# AT32UC3L0256 device description
Architecture: AVR32_UC3; Family: AVR UC3
Registers are 32-bit, read-write, reset 0x0 unless marked. A register's access mark holds for its fields unless they carry their own. Offsets are from the block's base; [hi:lo] are bit positions; lines under a group give offsets from that group; {n}, {i} and the like mark numbered series; 'fields as' and 'values as' point back to an identical list.

## GLOC — Glue Logic Controller
Instances: GLOC 0xffff6c00
{0x0+8i} LUT[{i}] (i=0..6) group
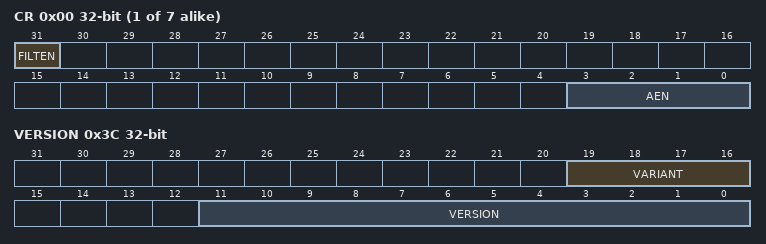
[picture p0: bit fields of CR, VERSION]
  0x00 CR — Control Register
    [31] FILTEN — Filter enable
    [3:0] AEN — Input mask
  0x04 TRUTH
    [15:0] TRUTH
0x38 PARAMETER ro reset not defined
  [7:0] LUTS
0x3C VERSION ro reset not defined
  [19:16] VARIANT, [11:0] VERSION

## HMATRIXB — HSB Matrix
Instances: HMATRIXB 0xfffe0400
{0x0+4i} mcfg[{i}] (i=0..15) access not given reset 0x2
  [2:0] ULBT — Undefined Length Burst Type
    0=INFINITE; 1=SINGLE; 2=FOUR_BEAT; 3=EIGHT_BEAT; 4=SIXTEEN_BEAT
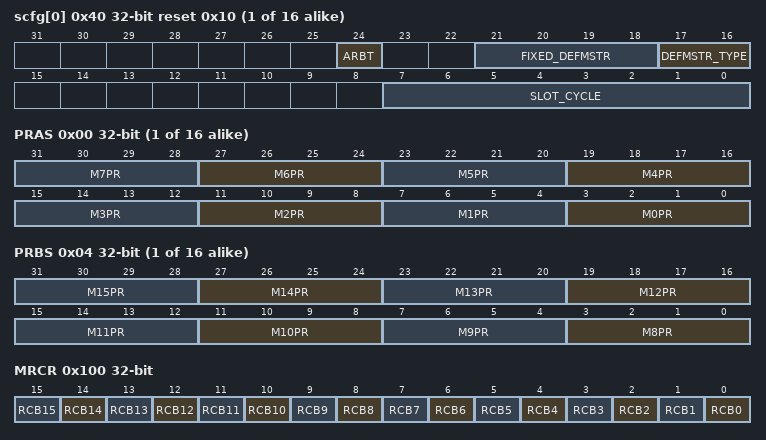
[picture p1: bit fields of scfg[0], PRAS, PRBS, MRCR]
{0x40+4i} scfg[{i}] (i=0..15) access not given reset 0x10
  [24] ARBT — Arbitration Type
    0=ROUND_ROBIN; 1=FIXED_PRIORITY
  [21:18] FIXED_DEFMSTR — Fixed Index of Default Master
  [17:16] DEFMSTR_TYPE — Default Master Type
    0=NO_DEFAULT; 1=LAST_DEFAULT; 2=FIXED_DEFAULT
  [7:0] SLOT_CYCLE — Maximum Number of Allowed Cycles for a Burst
{0x80+8i} prs[{i}] (i=0..15) group
  0x00 PRAS — Priority Register A for Slave 0
    [4n+3:4n] M{n}PR (n=0..7) — Master {n} Priority
  0x04 PRBS — Priority Register B for Slave 0
    [4n-29:4n-32] M{n}PR (n=8..15) — Master {n} Priority
0x100 MRCR — Master Remap Control Register
  [n] RCB{n} (n=0..15) — Remap Command bit for Master {n}
{0x110+4i} sfr[{i}] (i=0..15) access not given
  [31:0] SFR — Special Function Register

## PDCA — Peripheral DMA Controller
Instances: PDCA 0xffff0000
{0x0+0x40*i} channel[{i}] (i=0..31) group
  0x00 MAR — Memory Address Register
    [31:0] MADDR — Memory Address
  0x04 PSR reset not defined — Peripheral Select Register
    [7:0] PID — Peripheral Identifier
  0x08 TCR — Transfer Counter Register
    [15:0] TCV — Transfer Counter Value
  0x0C MARR — Memory Address Reload Register
    [31:0] MARV — Memory Address Reload Value
  0x10 TCRR — Transfer Counter Reload Register
    [15:0] TCRV — Transfer Counter Reload Value
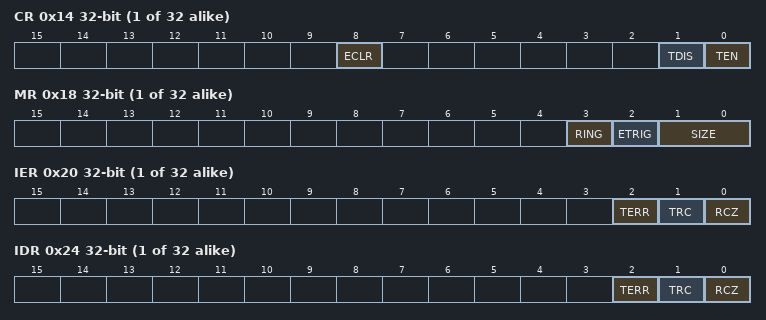
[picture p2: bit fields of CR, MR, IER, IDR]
  0x14 CR wo — Control Register
    [8] ECLR — Error Clear
    [1] TDIS — Transfer Disable
    [0] TEN — Transfer Enable
  0x18 MR — Mode Register
    [3] RING — Ring Buffer
    [2] ETRIG — Event trigger
    [1:0] SIZE — Transfer size
      0=Byte; 1=Half_Word; 2=Word
  0x1C SR ro — Status Register
    [0] TEN — Transfer Enabled
  0x20 IER wo — Interrupt Enable Register
    [2] TERR — Transfer Error
    [1] TRC — Transfer Complete
    [0] RCZ — Reload Counter Zero
  0x24 IDR wo — Interrupt Disable Register
    fields as channel[0].IER
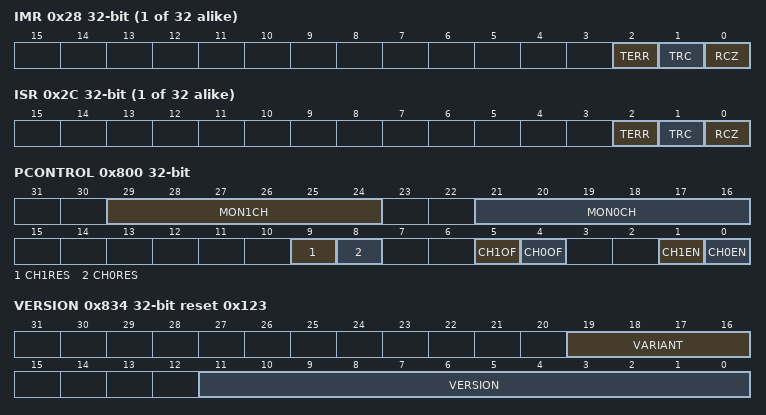
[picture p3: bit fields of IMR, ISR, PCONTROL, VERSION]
  0x28 IMR ro — Interrupt Mask Register
    fields as channel[0].IER
  0x2C ISR ro — Interrupt Status Register
    fields as channel[0].IER
0x800 PCONTROL — Performance Control Register
  [29:24] MON1CH — PDCA Channel to monitor with counter 1
  [21:16] MON0CH — PDCA Channel to monitor with counter 0
  [9] CH1RES — Channel 1 counter reset
  [8] CH0RES — Channel 0 counter reset
  [5] CH1OF — Channel 1 overflow freeze
  [4] CH0OF — Channel 0 Overflow Freeze
  [1] CH1EN — Channel 1 Enabled.
  [0] CH0EN — Channel 0 Enabled
0x804 PRDATA0 ro — Channel 0 Read Data Cycles
  [31:0] DATA — Data Cycles Counted Since Last reset
0x808 PRSTALL0 ro — Channel 0 Read Stall Cycles
  [31:0] STALL — Stall Cycles counted since last reset
0x80C PRLAT0 ro — Channel 0 Read Max Latency
  [15:0] LAT — Maximum Transfer Initiation cycles counted since last reset
0x810 PWDATA0 ro — Channel 0 Write Data Cycles
  [31:0] DATA — Data Cycles Counted since last Reset
0x814 PWSTALL0 ro — Channel 0 Write Stall Cycles
  [31:0] STALL — Stall cycles counted since last reset
0x818 PWLAT0 ro — Channel0 Write Max Latency
  [15:0] LAT — Maximum transfer initiation cycles counted since last reset
0x81C PRDATA1 ro — Channel 1 Read Data Cycles
  [31:0] DATA — Data Cycles Counted Since Last reset
0x820 PRSTALL1 ro — Channel Read Stall Cycles
  [31:0] STALL — Stall Cycles Counted since last reset
0x824 PRLAT1 ro — Channel 1 Read Max Latency
  [15:0] LAT — Maximum Transfer initiation cycles counted since last reset
0x828 PWDATA1 ro — Channel 1 Write Data Cycles
  [31:0] DATA — Data cycles Counted Since last reset
0x82C PWSTALL1 ro — Channel 1 Write stall Cycles
  [31:0] STALL — Stall cycles counted since last reset
0x830 PWLAT1 ro — Channel 1 Read Max Latency
  fields as PWLAT0
0x834 VERSION ro reset 0x123
  [19:16] VARIANT — Variant Number
  [11:0] VERSION — Version Number
